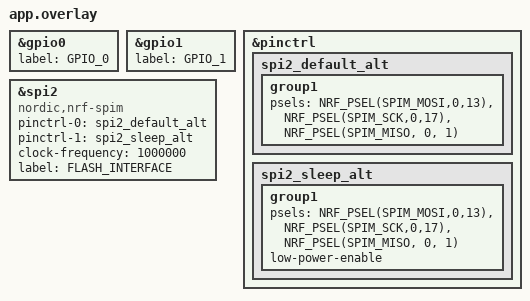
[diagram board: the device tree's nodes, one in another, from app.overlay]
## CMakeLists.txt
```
# SPDX-License-Identifier: Apache-2.0

cmake_minimum_required(VERSION 3.13.1)

find_package(Zephyr REQUIRED HINTS $ENV{ZEPHYR_BASE})
project(hello_world)

target_sources(app PRIVATE src/main.c src/ext_flash_mem.c )
zephyr_include_directories(${ZEPHYR_BASE}/boards/arm/bbc_microbit_v2)
```

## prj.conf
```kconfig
# nothing here
CONFIG_GPIO=y
CONFIG_SPI=y
CONFIG_SPI_NRFX=y

CONFIG_SERIAL=y
CONFIG_CONSOLE=y
```

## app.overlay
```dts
&gpio0 {
	status="okay";
	label="GPIO_0";
};
&gpio1 {
	status="okay";
	label="GPIO_1";
};
&pinctrl {
    /* IMPORTANT!  There should not be a space before the : in the next line (and similar below) */
    spi2_default_alt: spi2_default_alt {
        group1 {
            psels = <NRF_PSEL(SPIM_MOSI,0,13)>,
                    <NRF_PSEL(SPIM_SCK,0,17)>,
                    <NRF_PSEL(SPIM_MISO, 0, 1)>;
                    
        };                       
    };
    spi2_sleep_alt: spi2_sleep_alt {
        group1 {
            psels = <NRF_PSEL(SPIM_MOSI,0,13)>,
                    <NRF_PSEL(SPIM_SCK,0,17)>,
                    <NRF_PSEL(SPIM_MISO, 0, 1)>;
                    
            low-power-enable;
        };
    };
};
&spi2 {
	status = "enabled";  /* enabled at boot */
	compatible = "nordic,nrf-spim";
    status = "okay";
    pinctrl-0 = <&spi2_default_alt>;
    pinctrl-1 = <&spi2_sleep_alt>;
    // cs-gpios = <&gpio1 2 GPIO_ACTIVE_LOW>;
    pinctrl-names = "default", "sleep";
    clock-frequency = <1000000>;
    label = "FLASH_INTERFACE";
};
```

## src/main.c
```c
/*
 * SPDX-License-Identifier: Apache-2.0
 */

#include <zephyr/kernel.h>
#include <zephyr/sys/printk.h>
#include <zephyr/device.h>
#include "ext_flash_mem.h"
// Pin usage by SPI bus defined in app.overlay.	
int main(void)
{
	int ret=0;
	uint8_t txdata[]={0x05, 0x06,0x07,0x08};		
	uint8_t rxdata[10];
	init_spi();
	write_enable();	
//	sector_erase(0xfed00);
	page_program(0xfed04,txdata,4);	
	while(1)
	{				
		read_data(0xfed04,rxdata,4);
		printk("rxdata = %x %x %x %x\n",rxdata[0],rxdata[1],rxdata[2],rxdata[3]);		
		k_msleep(10);
		
	}
	return ret;
}
```

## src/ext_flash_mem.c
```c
#include <zephyr/kernel.h>
#include <zephyr/sys/printk.h>
#include <zephyr/drivers/gpio.h>
#include <zephyr/device.h>
#include <zephyr/drivers/spi.h>
// MX25L8005 Flash chip interface driver
static const struct spi_config cfg = {
	.frequency = 1000000,
	.operation = SPI_WORD_SET(8) | SPI_TRANSFER_MSB,
	.slave = 0	
};
static const struct device *flash_chip;
static const struct device *gpio1;
int init_spi()
{
	
	// Now configure the GPIO's for use as DC and Reset
	// The MISO pin (not used) will be reassigned as Reset
	int ret=0;
    gpio1=DEVICE_DT_GET(DT_NODELABEL(gpio1));
	if (gpio1==0)
	{
		printk("Error acquiring GPIO 1 interface\n");
	}
	gpio_pin_set(gpio1,2,1);
	ret = gpio_pin_configure(gpio1,2,GPIO_OUTPUT);
	flash_chip = device_get_binding("FLASH_INTERFACE");
	if (flash_chip==NULL)
	{
		printf("Error acquiring SPI interface\n");
		return -1;
	}
	else
	{
		printf("Got SPI interface\n");
		if (!device_is_ready(flash_chip))
		{
			printf("Device is not ready\n");
			return -2;
		}
	}	
	return ret;
}
void spi_exchange(uint8_t * tx_data, uint32_t tx_len, uint8_t * rx_data, uint32_t expected_rx_len)
{
	gpio_pin_set(gpio1,2,0);	
	struct spi_buf tx_buf = {.buf = tx_data, .len = tx_len};
	struct spi_buf rx_buf = {.buf = rx_data, .len = expected_rx_len};
	struct spi_buf_set tx_bufs = {.buffers = &tx_buf, .count = 1};
	struct spi_buf_set rx_bufs = {.buffers = &rx_buf, .count = 1};   
	spi_transceive(flash_chip, &cfg, &tx_bufs, &rx_bufs);
	gpio_pin_set(gpio1,2,1);
}

int read_electronic_signature(uint8_t *sig,uint32_t sig_len)
{
	uint8_t cmd=0x90;
	spi_exchange(&cmd,1,sig,sig_len); // should return the values 0x13 and 0xc2 in locations 4 and 5 in sig	
	return 0;
}
int read_status_register(uint8_t *stat)
{
	uint8_t cmd=0x05;
	uint8_t rxdata[2];
	spi_exchange(&cmd,1,rxdata,2); // should return the values 0xc2 and 0x13 in locations 4 and 5 in sig
	*stat=rxdata[1];
	return 0;
}
int write_status_register(uint8_t stat)
{
	uint8_t txdata[2];
	txdata[0]=0x04;
	txdata[1]=stat;	
	spi_exchange(txdata,2,NULL,0); // should return the values 0xc2 and 0x13 in locations 4 and 5 in sig
	return 0;
}
int busy() {
// Must now wait for write to complete.
// Poll the Write In Progess bit in the status register (LSB)
	uint8_t stat;
	read_status_register(&stat);
	return (stat & 1);
}
int write_enable()
{
	uint8_t cmd=0x06;
	spi_exchange(&cmd,1,NULL,0); // should return the values 0xc2 and 0x13 in locations 4 and 5 in sig
	return 0;
}
int write_disable()
{
	uint8_t cmd=0x04;
	spi_exchange(&cmd,1,NULL,0); // should return the values 0xc2 and 0x13 in locations 4 and 5 in sig
	return 0;
}
int power_down(void)
{
	uint8_t cmd=0xb9;
	spi_exchange(&cmd,1,NULL,0); // should return the values 0xc2 and 0x13 in locations 4 and 5 in sig	
	return 0;
}
int power_up(void)
{
	uint8_t cmd=0xab;
	spi_exchange(&cmd,1,NULL,0); // should return the values 0xc2 and 0x13 in locations 4 and 5 in sig	
	return 0;
}
int read_data(uint32_t address, uint8_t *data, uint32_t len)
{
	uint8_t txdata[4];
	txdata[0]=0x03;
	txdata[1]=address>>16;	
	txdata[2]=(address >> 8) & 0xff;
	txdata[3]=address & 0xff;	
	gpio_pin_set(gpio1,2,0);	// CS low

	struct spi_buf cmd_buf = {.buf = txdata, .len = 4};
	struct spi_buf_set cmd_bufs = {.buffers = &cmd_buf, .count = 1};	
	spi_transceive(flash_chip, &cfg, &cmd_bufs, NULL);

	struct spi_buf data_buf = {.buf = data, .len = len};
	struct spi_buf_set data_bufs = {.buffers = &data_buf, .count = 1};	
	spi_transceive(flash_chip, &cfg, NULL,&data_bufs);
	
	gpio_pin_set(gpio1,2,1); 	// CS High
	return 0;
}
int page_program(uint32_t address, uint8_t *data, uint32_t len) // program page.  8LSB's of address should be 0.  len <= 256;
{
	uint8_t txdata[5];
	txdata[0]=0x02;
	txdata[1]=address>>16;	
	txdata[2]=(address >> 8) & 0xff;
	txdata[3]=address & 0xff;
	
	gpio_pin_set(gpio1,2,0);	// CS low
	
	struct spi_buf cmd_buf = {.buf = txdata, .len = 4};
	struct spi_buf_set cmd_bufs = {.buffers = &cmd_buf, .count = 1};	
	spi_transceive(flash_chip, &cfg, &cmd_bufs, NULL);
	
	struct spi_buf data_buf = {.buf = data, .len = len};
	struct spi_buf_set data_bufs = {.buffers = &data_buf, .count = 1};	
	spi_transceive(flash_chip, &cfg, &data_bufs, NULL);

	
	gpio_pin_set(gpio1,2,1); 	// CS High
	
	while (busy())
	{
		printk(".");
	}
	return 0;
}
int sector_erase(uint32_t sector_address)
{
	uint8_t txdata[5];
	txdata[0]=0x20;
	txdata[1]=sector_address>>16;	
	txdata[2]=(sector_address >> 8) & 0xff;
	txdata[3]=0;
	
	gpio_pin_set(gpio1,2,0);	// CS low
	
	struct spi_buf cmd_buf = {.buf = txdata, .len = 4};
	struct spi_buf_set cmd_bufs = {.buffers = &cmd_buf, .count = 1};	
	spi_transceive(flash_chip, &cfg, &cmd_bufs, NULL);
	gpio_pin_set(gpio1,2,1); 	// CS High
	while (busy())
	{
		printk(".");
	};
	return 0;
}
int block_erase(uint32_t block_address)
{
	uint8_t txdata[5];
	txdata[0]=0x52;
	txdata[1]=block_address>>16;	
	txdata[2]=(block_address >> 8) & 0xff;
	txdata[3]=0;
	
	gpio_pin_set(gpio1,2,0);	// CS low
	
	struct spi_buf cmd_buf = {.buf = txdata, .len = 4};
	struct spi_buf_set cmd_bufs = {.buffers = &cmd_buf, .count = 1};	
	spi_transceive(flash_chip, &cfg, &cmd_bufs, NULL);
	gpio_pin_set(gpio1,2,1); 	// CS High
	while (busy())
	{
		printk(".");
	};
	return 0;
}
int chip_erase()
{
	uint8_t txdata[5];
	txdata[0]=0x60;
		
	gpio_pin_set(gpio1,2,0);	// CS low
	
	struct spi_buf cmd_buf = {.buf = txdata, .len = 1};
	struct spi_buf_set cmd_bufs = {.buffers = &cmd_buf, .count = 1};	
	spi_transceive(flash_chip, &cfg, &cmd_bufs, NULL);
	gpio_pin_set(gpio1,2,1); 	// CS High
	// show a "spinning" line on the console to indicate that we are waiting for chip erase to finish
	char spin[]="\\|/-";
	int spin_index=0;
	printk("\n");
	while (busy())
	{
		printk("\r%c",spin[spin_index]);
		spin_index++;
		if (spin_index >3)
			spin_index = 0;
		k_msleep(10);
	};	
	printk("\n");
	return 0;
}
```

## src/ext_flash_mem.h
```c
#ifndef __EXT_FLASH_MEM_H
#define __EXT_FLASH_MEM_H
// Some terminology
// A page is a 256 Byte section of memory
// A sector is a 4096 Byte section of memory
// A block is a 65536 Byte (64kB) section of memory
// Can write pages
// Can erase sectors or block or the entire chip
// Wiring (uses SPI 2 in NRF52833)
// CS : Port 1, bit 2
// MOSI : Port 0, bit 13
// MISO : Port 0, bit 1 
// SCK : Port 0, bit 17
// HOLD : pulled high to 3.3V using a few kOhms
// WP : pulled high to 3.3V using a few kOhms

int init_spi(void);
void spi_exchange(uint8_t * tx_data, uint32_t tx_len, uint8_t * rx_data, uint32_t expected_rx_len);
int read_electronic_signature(uint8_t *sig,uint32_t sig_len);

int write_enable(void);
int write_disable(void);
int read_status_register(uint8_t *status);
int write_status_register(uint8_t status);
int power_down(void);
int power_up(void);
int read_data(uint32_t address, uint8_t *data, uint32_t len);
int page_program(uint32_t address, uint8_t *data, uint32_t len); // program page.  8LSB's of address should be 0.  len <= 256;
int sector_erase(uint32_t sector_address);
int block_erase(uint32_t block_address);
int chip_erase();
int busy();
#endif
```
